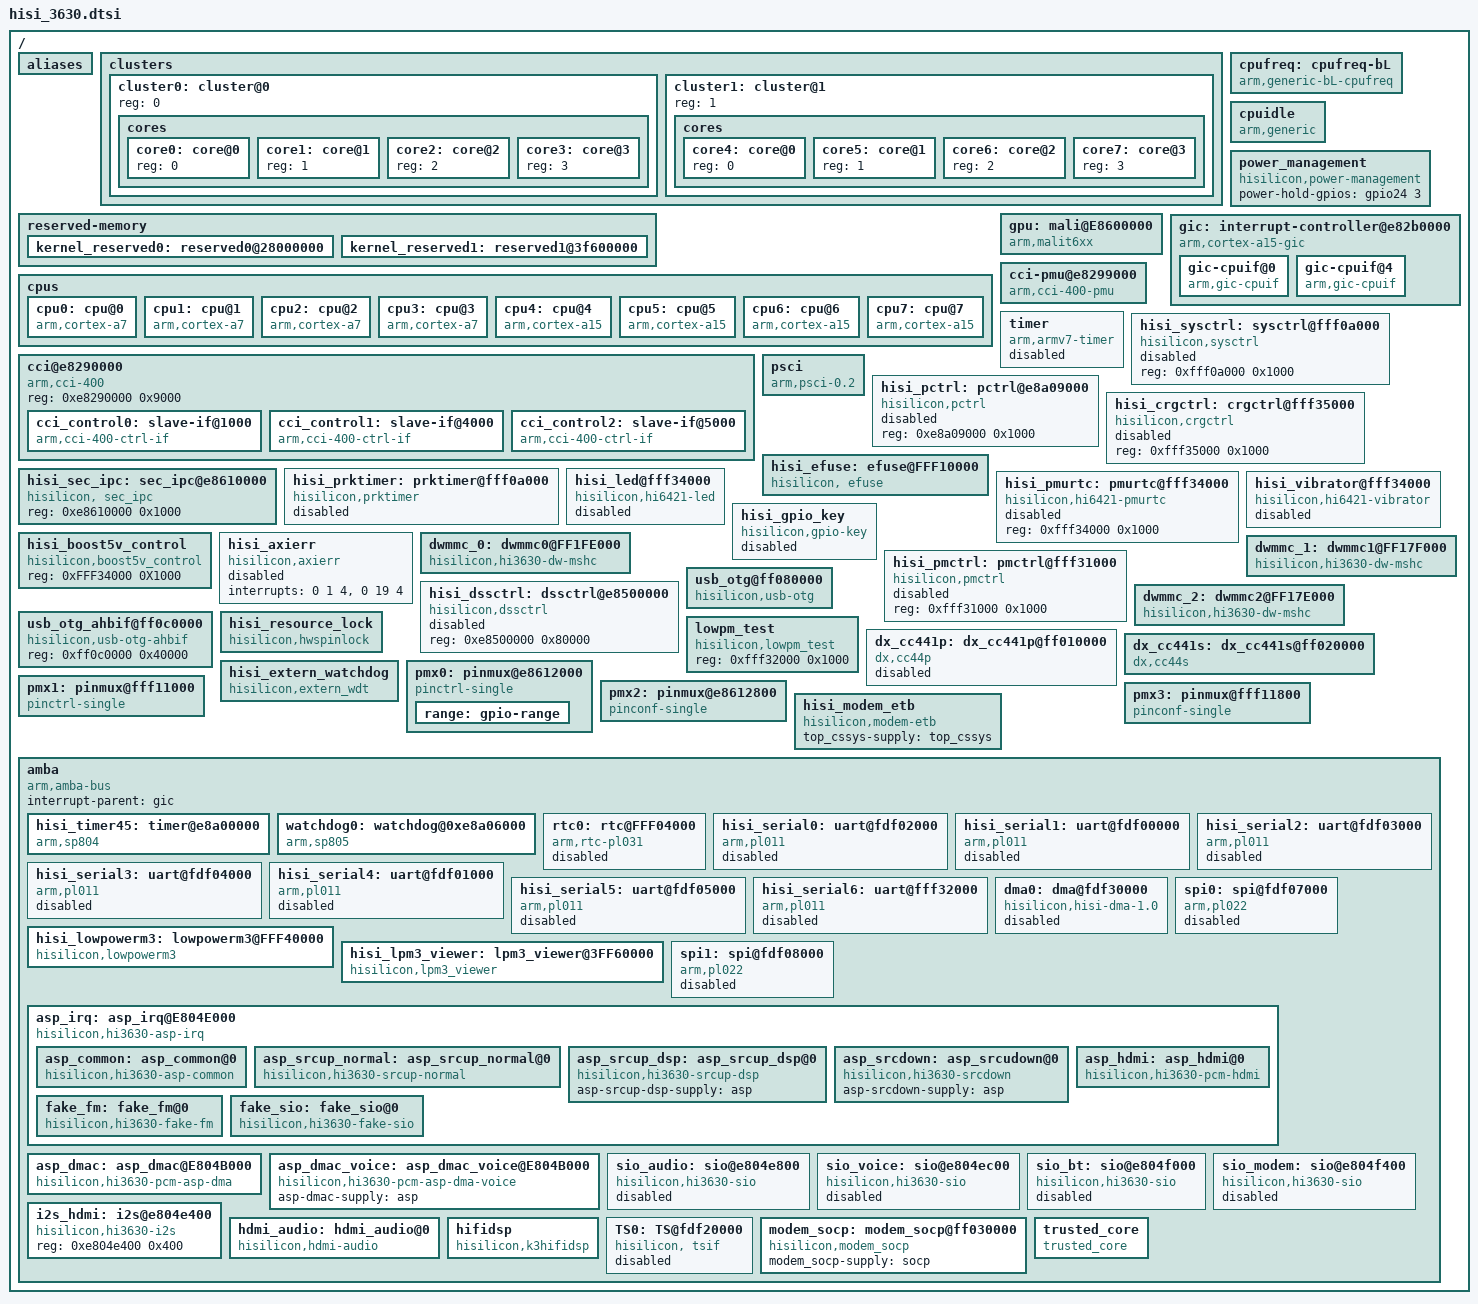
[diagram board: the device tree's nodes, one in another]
/*
 * Hisilicon Ltd. Hi3630FPGA SoC
 *
 * Copyright (C) 2013 Hisilicon Technologies CO., Ltd.
 *
 * This program is free software; you can redistribute it and/or modify
 * it under the terms of the GNU General Public License version 2 as
 * publishhed by the Free Software Foundation.
 */

/include/ "skeleton.dtsi"
/include/ "hisi_3630_clock.dtsi"
/include/ "hisi_3630_gpio.dtsi"
/include/ "hisi_3630_i2c.dtsi"
/include/ "hisi_3630_ipc.dtsi"
/{
	aliases {
		serial0 = &hisi_serial0;
	        serial1 = &hisi_serial1;
	        serial2 = &hisi_serial2;
	        serial3 = &hisi_serial3;
	        serial4 = &hisi_serial4;
	        serial5 = &hisi_serial5;
		serial6 = &hisi_serial6;

		mshc0 = &dwmmc_0;
		mshc1 = &dwmmc_1;
		mshc2 = &dwmmc_2;
	};

	clusters {
		#address-cells = <1>;
		#size-cells = <0>;

		cluster0: cluster@0 { /*A15 cluster*/
			reg = <0>;
			cores {
				#address-cells = <1>;
				#size-cells = <0>;

				core0: core@0 {
					reg = <0>;
				};

				core1: core@1 {
					reg = <1>;
				};

				core2: core@2 {
					reg = <2>;
				};

				core3: core@3 {
					reg = <3>;
				};

			};
		};

		cluster1: cluster@1 { /*A7 cluster*/
			reg = <1>;
			cores {
				#address-cells = <1>;
				#size-cells = <0>;

				core4: core@0 {
					reg = <0>;
				};

				core5: core@1 {
					reg = <1>;
				};

				core6: core@2 {
					reg = <2>;
				};

				core7: core@3 {
					reg = <3>;
				};
			};
		};
	};
	
	reserved-memory {
		#address-cells = <1>;
		#size-cells = <1>;
		ranges;

		kernel_reserved0: reserved0@28000000 {
			reg = <0x28000000 0x12a00000>;
			no-map;
		};

		kernel_reserved1: reserved1@3f600000 {
			reg = <0x3f600000 0x00a00000>;
			no-map;
		};

	};
	
	cpus {
		#address-cells = <1>;
		#size-cells = <0>;

		cpu0: cpu@0 {
			device_type = "cpu";
			compatible = "arm,cortex-a7";
			cci-control-port = <&cci_control1>;
			reg = <0x100>;
			cluster = <&cluster1>;
			core = <&core4>;
			clock-frequency = <0>;
			clock-latency = <0>;
			operating-points = <
				/* kHz */
				403200  0
				604800  0
				806400  0
				1017600 0
				1209600 0
				1305600 0
				/* 1401600 0 */
				/* 1612800 0 */
			>;
		};

		cpu1: cpu@1 {
			device_type = "cpu";
			compatible = "arm,cortex-a7";
			cci-control-port = <&cci_control1>;
			reg = <0x101>;
			cluster = <&cluster1>;
			core = <&core5>;
			clock-frequency = <0>;
			clock-latency = <0>;
		};

		cpu2: cpu@2 {
			device_type = "cpu";
			compatible = "arm,cortex-a7";
			cci-control-port = <&cci_control1>;
			reg = <0x102>;
			cluster = <&cluster1>;
			core = <&core6>;
			clock-frequency = <0>;
			clock-latency = <0>;
		};

		cpu3: cpu@3 {
			device_type = "cpu";
			compatible = "arm,cortex-a7";
			cci-control-port = <&cci_control1>;
			reg = <0x103>;
			cluster = <&cluster1>;
			core = <&core7>;
			clock-frequency = <0>;
			clock-latency = <0>;
		};

		cpu4: cpu@4 {
			device_type = "cpu";
			compatible = "arm,cortex-a15";
			cci-control-port = <&cci_control2>;
			reg = <0>;
			cluster = <&cluster0>;
			core = <&core0>;
			clock-frequency = <0>;
			clock-latency = <0>;
			operating-points = <
				/* kHz */
				/* 508800  0 */
				806400  0
				1017600 0
				1209600 0
				1382400 0
				1497600 0
				1708800 0
				/* 1804800 0 */
			>;
		};

		cpu5: cpu@5 {
			device_type = "cpu";
			compatible = "arm,cortex-a15";
			cci-control-port = <&cci_control2>;
			reg = <1>;
			cluster = <&cluster0>;
			core = <&core1>;
			clock-frequency = <0>;
			clock-latency = <0>;
		};

		cpu6: cpu@6 {
			device_type = "cpu";
			compatible = "arm,cortex-a15";
			cci-control-port = <&cci_control2>;
			reg = <2>;
			cluster = <&cluster0>;
			core = <&core2>;
			clock-frequency = <0>;
			clock-latency = <0>;
		};

		cpu7: cpu@7 {
			device_type = "cpu";
			compatible = "arm,cortex-a15";
			cci-control-port = <&cci_control2>;
			reg = <3>;
			cluster = <&cluster0>;
			core = <&core3>;
			clock-frequency = <0>;
			clock-latency = <0>;
		};
	};

	/* cpufreq  device */
	cpufreq: cpufreq-bL {
		compatible = "arm,generic-bL-cpufreq";
	};

    cpuidle {
        compatible = "arm,generic";
        status = "ok";
    };

	power_management {
		compatible = "hisilicon,power-management";
		power-hold-gpios = <&gpio24 3 0>;
	};

	gpu: mali@E8600000 {
		compatible = "arm,malit6xx", "arm,mali-midgard";
                reg = <0xE8600000 0x4000>;
                interrupts = <0 137 4  0 138 4  0 139 4>;
                interrupt-names = "JOB", "MMU", "GPU";
		clocks = <&clk_g3d>;
		gpu-supply = <&g3d>;
		operating-points = <
			/* kHz */
			288000 0
			360000 0
			480000 0
			600000 0
			/* 720000 0 */
		>;
	};

	gic: interrupt-controller@e82b0000 {
		compatible = "arm,cortex-a15-gic", "arm,cortex-a7-gic";
		#interrupt-cells = <3>;
		#address-cells = <0>;
		interrupt-controller;
		reg =	<0xe82b1000 0x1000>,
			<0xe82b2000 0x1000>,
			<0xe82b4000 0x2000>,
			<0xe82b6000 0x2000>;
		interrupts = <1 9 0xf04>;
		/*In our system, a15 cluster is in range cpuif0/cpuif1/cpuif2/cpuif3
		* a7 cluster is in range cpuif4/cpuif5/cpuif6/cpuif7
		*/
		gic-cpuif@0 {
			compatible = "arm,gic-cpuif";
			cpuif-id = <0>;
			cpu = <&cpu1>;
		};

		gic-cpuif@4 {
			compatible = "arm,gic-cpuif";
			cpuif-id = <4>;
			cpu = <&cpu0>;
		};
	};

        cci@e8290000 {
                compatible = "arm,cci-400";
                #address-cells = <1>;
                #size-cells = <1>;
                reg = <0xe8290000 0x9000>;
                ranges = <0x1000 0xe8291000 0x1000>,
			<0x4000 0xe8294000 0x1000>,
			<0x5000 0xe8295000 0x1000>;

                cci_control0: slave-if@1000 {
                        compatible = "arm,cci-400-ctrl-if";
                        interface-type = "ace-lite";
                        reg = <0x1000 0x1000>;
                };

                cci_control1: slave-if@4000 {
                        compatible = "arm,cci-400-ctrl-if";
                        interface-type = "ace";
                        reg = <0x4000 0x1000>;
                };

                cci_control2: slave-if@5000 {
                        compatible = "arm,cci-400-ctrl-if";
                        interface-type = "ace";
                        reg = <0x5000 0x1000>;
                };
        };

        cci-pmu@e8299000 {
                compatible = "arm,cci-400-pmu";
                reg = <0xe8299000 0x6000>;
                interrupts = <0 106 4>,
                             <0 107 4>;
        };

	timer {
		compatible = "arm,armv7-timer";
		interrupt-parent = <&gic>;
		clock-frequency = <19200000>;
		interrupts =
			<1 13 0xf08>,
			<1 14 0xf08>,
			<1 11 0xf08>,
			<1 10 0xf08>;
		status = "disabled";
	};

	hisi_sysctrl: sysctrl@fff0a000 {
		compatible = "hisilicon,sysctrl";
		reg = <0xfff0a000 0x1000>;
		status = "disabled";
	};

	psci {
		compatible      = "arm,psci-0.2", "arm,psci";
		method          = "smc";
		cpu_suspend     = <0x80100001>;
		cpu_off         = <0x80100002>;
		cpu_on          = <0x80100003>;
		migrate         = <0x80100004>;
		system_off      = <0x80100008>;
		system_reset    = <0x80100009>;
	};
	hisi_pctrl: pctrl@e8a09000 {
		compatible = "hisilicon,pctrl";
		reg = <0xe8a09000 0x1000>;
		status = "disabled";
	};

	hisi_crgctrl: crgctrl@fff35000 {
		compatible = "hisilicon,crgctrl";
		reg = <0xfff35000 0x1000>;
		status = "disabled";
	};

	hisi_efuse: efuse@FFF10000 {
		compatible = "hisilicon, efuse";
		reg = <0xFFF10000 0x1000>;
		efuse-burning-supply = <&ldo6>;
	};

	hisi_sec_ipc: sec_ipc@e8610000 {
		compatible = "hisilicon, sec_ipc";
		reg = <0xe8610000 0x1000>;
	};

	hisi_prktimer: prktimer@fff0a000 {
		compatible = "hisilicon,prktimer";
		fpga_flag = <0>;
		reg = <0xfff0a000 0x1000>;
		status = "disabled";
	};

	hisi_pmurtc: pmurtc@fff34000 {
		compatible = "hisilicon,hi6421-pmurtc";
		reg = <0xfff34000 0x1000>;
		status = "disabled";
	};

	hisi_led@fff34000 {
		compatible = "hisilicon,hi6421-led";
		reg = <0xfff34000 0x1000>;
		hi6421,dr3ctrl = "red";
		hi6421,dr4ctrl = "green";
		hi6421,dr5ctrl = "blue";
		status = "disabled";
	};

	hisi_vibrator@fff34000 {
		compatible = "hisilicon,hi6421-vibrator";
		reg = <0xfff34000 0x1000>;
		/* 1 vibrator working LRA,0 working ERM*/
		hisi,erm_lra = <1>;
		/* 0:2.7V  1:2.8V 2:3.0V 3:3.3V */
		hisi,dr2_test = <3>;
		/*20H:0V  3FH:max lm_dr2 00H:MIN -lm_dr2 */
		hisi,dr2_vset = <0x3f>;
		/* LRA mode ocp enable,1 : enable,0 : disable*/
		hisi,ocp_en = <1>;
		/* 0 : 4 ocp cycle ,1 : 8 ocp sycle*/
		hisi,ocp_sel = <0>;
		/*LRA mode get current change frequency*/
		hisi,freq = <0x20>;
		/*"enabled": create dev/tspdrv node,"disabled": no dev/tspdrv node*/
		hw,immersion = "disabled";
		status = "disabled";
	};

	hisi_gpio_key {
		compatible = "hisilicon,gpio-key";
		pinctrl-names = "default", "idle";
		pinctrl-0 = <&gpio203_cfg_func &gpio204_cfg_func>;
		pinctrl-1 = <&gpio203_cfg_idle &gpio204_cfg_idle>;
		gpio-keyup,gpio-irq = <&gpio25 3 0>;
		gpio-keydown,gpio-irq = <&gpio25 4 0>;
		status = "disabled";
	};

	hisi_boost5v_control {
		compatible = "hisilicon,boost5v_control";
		reg = <0xFFF34000 0X1000>;
		status = "ok";
	};

	hisi_axierr {
		compatible = "hisilicon,axierr";
		interrupts = <0 1 4>, <0 19 4>;
		status = "disabled";
	};

	/* emmc */
	dwmmc_0: dwmmc0@FF1FE000 {
		compatible = "hisilicon,hi3630-dw-mshc";
		reg = <0xFF1FE000 0x1000>;
		interrupts = <0 118 4>;
		#address-cells = <1>;
		#size-cells = <0>;
		clocks = <&clk_gate_mmc0>, <&clk_ppll0>;
		clock-names = "ciu", "biu";
	};

	/* sd */
	dwmmc_1: dwmmc1@FF17F000 {
		compatible = "hisilicon,hi3630-dw-mshc";
		reg = <0xFF17F000 0x1000>;
		interrupts = <0 119 4>;
		#address-cells = <1>;
		#size-cells = <0>;
		clocks = <&clk_gate_mmc1>, <&clk_ppll0>;
		clock-names = "ciu", "biu";
	};

	hisi_pmctrl: pmctrl@fff31000 {
		compatible = "hisilicon,pmctrl";
		reg = <0xfff31000 0x1000>;
		status = "disabled";
	};

	hisi_dssctrl: dssctrl@e8500000 {
		compatible = "hisilicon,dssctrl";
		reg = <0xe8500000 0x80000>;
		status = "disabled";
	};

	/* SDIO */
	dwmmc_2: dwmmc2@FF17E000 {
		compatible = "hisilicon,hi3630-dw-mshc";
		reg = <0xFF17E000 0x1000>;
		interrupts = <0 120 4>;
		#address-cells = <1>;
		#size-cells = <0>;
		clocks = <&clk_gate_mmc2>, <&clk_ppll0>;
		clock-names = "ciu", "biu";
	};

	usb_otg@ff080000 {
		compatible = "hisilicon,usb-otg";
		reg = <0xff080000 0x40000>;
		interrupts = <0 115 0x4>;
		otgdebugsubsys-supply = <&usb2otg>;
		eyePattern = <0x01ee66e7>;
	};

	usb_otg_ahbif@ff0c0000 {
		compatible = "hisilicon,usb-otg-ahbif";
		reg = <0xff0c0000 0x40000>;
	};

	hisi_resource_lock {
		compatible = "hisilicon,hwspinlock";
		hwlock,register-width = <32>;
		hwlock,bits-per-single = <4>;
		hwlock,groups = <8>;
		hwlock,offset = <0x400>, <0x40c>, <0x418>,
					<0x424>, <0x800>, <0x80c>,
					<0x818>, <0x824>;
	};

       lowpm_test {
               compatible = "hisilicon,lowpm_test";
	       reg = <0xfff32000 0x1000>;
       };

	dx_cc441p: dx_cc441p@ff010000 {
		compatible = "dx,cc44p";
		reg = <0xff010000 0x10000>;
		sec-p-buring-supply = <&sec_p>;
		interrupt-parent = <&gic>;
		interrupts = <0 109 4>;
		status = "disabled";
	};

	dx_cc441s: dx_cc441s@ff020000 {
		compatible = "dx,cc44s";
		reg = <0xff020000 0x10000>;
                sec-s-buring-supply = <&sec_s>;
	};

	hisi_extern_watchdog {
		compatible = "hisilicon,extern_wdt";
		reg = <0xe804d000 0x1000>;
		interrupts = <0 170 4>, <0 171 4>, <0 210 4>, <0 205 4>;
		status = "ok";
	};

	pmx0: pinmux@e8612000 {
		compatible = "pinctrl-single", "pinctrl-single0";
		reg = <0xe8612000 0x1f8>;
		#address-cells = <1>;
		#size-cells = <1>;
		#gpio-range-cells = <3>;
		ranges;

		pinctrl-single,register-width = <32>;
		pinctrl-single,function-mask = <7>;
		/* pin base, nr pins & gpio function */
		pinctrl-single,gpio-range = <&range 0 126 0>;

		range: gpio-range {
			#pinctrl-single,gpio-range-cells = <3>;
		};
	};

	pmx1: pinmux@fff11000 {
		compatible = "pinctrl-single", "pinctrl-single1";
		reg = <0xfff11000 0x84>;
		#address-cells = <1>;
		#size-cells = <1>;
		#gpio-range-cells = <3>;
		ranges;

		pinctrl-single,register-width = <32>;
		pinctrl-single,function-mask = <7>;
		/* pin base, nr pins & gpio function */
		pinctrl-single,gpio-range = <&range 0 33 0>;
	};

	pmx2: pinmux@e8612800 {
		compatible = "pinconf-single", "pinctrl-single2";
		reg = <0xe8612800 0x2c4>;
		#address-cells = <1>;
		#size-cells = <1>;
		ranges;

		pinctrl-single,register-width = <32>;
	};

	pmx3: pinmux@fff11800 {
		compatible = "pinconf-single", "pinctrl-single3";
		reg = <0xfff11800 0x98>;
		#address-cells = <1>;
		#size-cells = <1>;
		ranges;

		pinctrl-single,register-width = <32>;
	};

	hisi_modem_etb {
                compatible = "hisilicon,modem-etb";
                top_cssys-supply = <&top_cssys>;
                status = "ok";
        };

	amba{
		#address-cells = <1>;
		#size-cells = <1>;
		compatible = "arm,amba-bus";
		interrupt-parent = <&gic>;
		ranges;

		/*hisi_timer01: timer@fff00000 {
			compatible = "arm,sp804", "arm,primecell";
			reg = <0xfff00000 0x1000>;
			clocks = <&clk_gate_timclk0 &clk_gate_timclk0 &pclk>;
			clock-names = "clk_timclk0", "clk_timclk1","apb_pclk";
			interrupts = <0 36 4>,<0 37 4>;
			status = "disabled";
		};*/

		hisi_timer45: timer@e8a00000 {
			compatible = "arm,sp804", "arm,primecell";
			reg = <0xe8a00000 0x1000>;
			clocks = <&clk_gate_timclk4 &clk_gate_timclk4 &pclk>;
			clock-names = "clk_timclk4", "clk_timclk5","apb_pclk";
			interrupts = <0 44 4>,<0 45 4>;
			status = "ok";
		};

		watchdog0: watchdog@0xe8a06000 {
			compatible = "arm,sp805", "arm,primecell";
			reg = <0xe8a06000 0x1000>;
			default-timeout = <20>;
			interrupts = <0 52 4>;
			clocks = <&pclk_gate_wd0 &pclk>;
			clock-names = "pclk_wd0", "apb_pclk";
			status = "ok";
		};

		rtc0: rtc@FFF04000 {
				compatible = "arm,rtc-pl031", "arm,primecell";
				reg = <0xfff04000 0x1000>;
				interrupts = <0 54 0x4>;
				clocks = <&pclk>;
				clock-names = "apb_pclk";
				status = "disabled";
		};

		hisi_serial0: uart@fdf02000 {
			compatible = "arm,pl011", "arm,primecell";
			reg = <0xfdf02000 0x1000>;
			interrupts = <0 56 4>;
			fifo-deep-size = <64>;
			clk-enable-flag = <1>;
			clock-freq-high = <0>;
			clocks = <&clk_gate_uart0 &pclk>;
			clock-names = "clk_uart0", "apb_pclk";
			status = "disabled";
		};

		hisi_serial1: uart@fdf00000 {
			compatible = "arm,pl011", "arm,primecell";
			reg = <0xfdf00000 0x1000>;
			interrupts = <0 57 4>;
			dmas =	<&dma0 2          /* read channel */
				 &dma0 3>;        /* write channel */
			dma-names = "rx", "tx";
			fifo-deep-size = <64>;
			clk-enable-flag = <1>;
			clock-freq-high = <0>;
			clocks = <&clk_gate_uart1 &clk_gate_uart1>;
			clock-names = "clk_uart1", "apb_pclk";
			status = "disabled";
		};

		hisi_serial2: uart@fdf03000 {
			compatible = "arm,pl011", "arm,primecell";
			reg = <0xfdf03000 0x1000>;
			interrupts = <0 58 4>;
			dmas =	<&dma0 4	  /* read channel */
				 &dma0 5>;	  /* write channel */
			dma-names = "rx", "tx";
			fifo-deep-size = <64>;
			clk-enable-flag = <1>;
			clock-freq-high = <0>;
			clocks = <&clk_gate_uart2 &pclk>;
			clock-names = "clk_uart2", "apb_pclk";
			status = "disabled";

		};

		hisi_serial3: uart@fdf04000 {
			compatible = "arm,pl011", "arm,primecell";
			reg = <0xfdf04000 0x1000>;
			interrupts = <0 59 4>;

			dmas =	<&dma0 6	  /* read channel */
				 &dma0 7>;	  /* write channel */
			dma-names = "rx", "tx";

			fifo-deep-size = <64>;
			clk-enable-flag = <1>;
			clock-freq-high = <0>;
			clocks = <&clk_gate_uart3 &clk_gate_uart3>;
			clock-names = "clk_uart3", "apb_pclk";
			status = "disabled";
		};

		hisi_serial4: uart@fdf01000 {
			compatible = "arm,pl011", "arm,primecell";
			reg = <0xfdf01000 0x1000>;
			interrupts = <0 60 4>;
			dmas =	<&dma0 8	  /* read channel */
				 &dma0 9>;	  /* write channel */
			dma-names = "rx", "tx";
			fifo-deep-size = <64>;
			clk-enable-flag = <1>;
			clock-freq-high = <1>;
			clocks = <&clk_gate_uart4 &clk_gate_uart4>;
			clock-names = "clk_uart4", "apb_pclk";
			status = "disabled";
		};

		hisi_serial5: uart@fdf05000 {
			compatible = "arm,pl011", "arm,primecell";
			reg = <0xfdf05000 0x1000>;
			interrupts = <0 61 4>;
			dmas =	<&dma0 10	   /* read channel */
				 &dma0 11>;	   /* write channel */
			dma-names = "rx", "tx";
			fifo-deep-size = <64>;
			clk-enable-flag = <1>;
			clock-freq-high = <0>;
			clocks = <&clk_gate_uart5 &clk_gate_uart5>;
			clock-names = "clk_uart5", "apb_pclk";
			status = "disabled";

		};

		hisi_serial6: uart@fff32000 {
			compatible = "arm,pl011", "arm,primecell";
			reg = <0xfff32000 0x1000>;
			interrupts = <0 62 4>;
			fifo-deep-size = <64>;
			clk-enable-flag = <1>;
			clock-freq-high = <0>;
			clocks = <&clk_uart6 &pclk>;
			clock-names = "uart6clk", "apb_pclk";
			status = "disabled";
		};

		dma0: dma@fdf30000 {
			compatible = "hisilicon,hisi-dma-1.0";
			reg = <0xfdf30000 0x1000>;
			#dma-cells = <1>;
			dma-channels = <16>;
			dma-requests = <27>;
			dma-min-chan = <1>;
			dma-used-chans = <0xFFFE>;
			interrupts = <0 121 4>;
			clocks = <&clk_gate_dmac &pclk>;
			clock-names = "clk_dmac", "apb_pclk";
			status = "disabled";
		};

		hisi_lowpowerm3: lowpowerm3@FFF40000 {
			compatible = "hisilicon,lowpowerm3";
			reg = <0xFFF40000 0x18000>, <0xFFF34000 0x2000>;
			interrupts = <0 171 4>;
			clocks = <&clk_gate_dmac>;
			clock-names = "clk_dmac";
		};

		hisi_lpm3_viewer: lpm3_viewer@3FF60000 {
			compatible = "hisilicon,lpm3_viewer";
			reg = <0x3FF60000 0x20000>;
			period_time = <0>;
			status = "ok";
		};

		spi0: spi@fdf07000 {
			compatible = "arm,pl022", "arm,primecell";
			reg = <0xfdf07000 0x1000>;
			interrupts = <0 63 4>;
			clocks = <&clk_gate_spi0 &clk_gate_spi0>;
			clock-names = "clk_spi0", "apb_pclk";
			bus-id = <0>;
			enable-dma = <1>;
			dmas =	<&dma0 12	   /* read channel */
				 &dma0 13>;	   /* write channel */
			dma-names = "rx", "tx";
			num-cs = <4>;
			hardware-mutex = <0>;
			status = "disabled";
		};

		spi1: spi@fdf08000 {
			compatible = "arm,pl022", "arm,primecell";
			reg = <0xfdf08000 0x1000>;
			interrupts = <0 64 4>;
			clocks = <&clk_gate_spi1 &clk_gate_spi1>;
			clock-names = "clk_spi1", "apb_pclk";
			bus-id = <1>;
			enable-dma = <1>;
			dmas =	<&dma0 14	   /* read channel */
				 &dma0 15>;	   /* write channel */
			dma-names = "rx", "tx";
			num-cs = <1>;
			hardware-mutex = <0>;
			status = "disabled";
		};

		asp_irq: asp_irq@E804E000 {
			compatible = "hisilicon,hi3630-asp-irq";
			reg = <0xE804E000 0xA000>;
			#interrupt-cells = <2>;
			interrupt-controller;
			interrupts = <0 136 4>;
			interrupt-names = "asp_irq";
			status = "ok";
			asp_common: asp_common@0 {
				compatible = "hisilicon,hi3630-asp-common";
				status = "ok";
			};
			asp_srcup_normal: asp_srcup_normal@0 {
				compatible = "hisilicon,hi3630-srcup-normal";
				interrupt-parent = <&asp_irq>;
				interrupts = <1 0>;
				interrupt-names = "asp_srcup_normal";
				asp-srcup-normal-supply = <&asp>;
				status = "ok";
			};
			asp_srcup_dsp: asp_srcup_dsp@0 {
				compatible = "hisilicon,hi3630-srcup-dsp";
				asp-srcup-dsp-supply = <&asp>;
				status = "ok";
			};
			asp_srcdown: asp_srcudown@0 {
				compatible = "hisilicon,hi3630-srcdown";
				asp-srcdown-supply = <&asp>;
				status = "ok";
			};
			asp_hdmi: asp_hdmi@0 {
				compatible = "hisilicon,hi3630-pcm-hdmi";
				interrupt-parent = <&asp_irq>;
				interrupts = <0 0>;
				interrupt-names = "asp_irq_hdmi";
				hdmi-pcm-supply = <&asp>;
			};
			fake_fm: fake_fm@0 {
				compatible = "hisilicon,hi3630-fake-fm";
				status = "ok";
			};
			fake_sio: fake_sio@0 {
				compatible = "hisilicon,hi3630-fake-sio";
				status = "ok";
			};
		};
		asp_dmac: asp_dmac@E804B000 {
			compatible = "hisilicon,hi3630-pcm-asp-dma";
			reg = <0xE804B000 0x1000>;
			interrupts = <0 213 4>;
			interrupt-names = "asp_dma_irq";
			asp-dmac-supply = <&asp>;
			status = "ok";
		};
		asp_dmac_voice: asp_dmac_voice@E804B000 {
			compatible = "hisilicon,hi3630-pcm-asp-dma-voice";
			asp-dmac-supply = <&asp>;
			status = "ok";
		};
		sio_audio: sio@e804e800 {
			compatible = "hisilicon,hi3630-sio";
			reg = <0xe804e800 0x400>;
			sio-audio-supply = <&asp>;
			pinctrl-names = "default", "idle";
			pinctrl-0 = <&gpio183_pmx_func
				     &gpio184_pmx_func
				     &gpio185_pmx_func
				     &gpio186_pmx_func
				     &gpio183_cfg_func
				     &gpio184_cfg_func
				     &gpio185_cfg_func
				     &gpio186_cfg_func>;
			pinctrl-1 = <&gpio183_pmx_idle
				     &gpio184_pmx_idle
				     &gpio185_pmx_idle
				     &gpio186_pmx_idle
				     &gpio183_cfg_idle
				     &gpio184_cfg_idle
				     &gpio185_cfg_idle
				     &gpio186_cfg_idle>;
			status = "disable";
		};
		sio_voice: sio@e804ec00 {
			compatible = "hisilicon,hi3630-sio";
			reg = <0xe804ec00 0x400>;
			sio-voice-supply = <&asp>;
			pinctrl-names = "default", "idle";
			pinctrl-0 = <&gpio043_pmx_func
				     &gpio044_pmx_func
				     &gpio045_pmx_func
				     &gpio046_pmx_func
				     &gpio043_cfg_func
				     &gpio044_cfg_func
				     &gpio045_cfg_func
				     &gpio046_cfg_func>;
			pinctrl-1 = <&gpio043_pmx_idle
				     &gpio044_pmx_idle
				     &gpio045_pmx_idle
				     &gpio046_pmx_idle
				     &gpio043_cfg_idle
				     &gpio044_cfg_idle
				     &gpio045_cfg_idle
				     &gpio046_cfg_idle>;
			status = "disable";
		};
		sio_bt: sio@e804f000 {
			compatible = "hisilicon,hi3630-sio";
			reg = <0xe804f000 0x400>;
			sio-bt-supply = <&asp>;
			/*
			pinctrl-names = "default", "idle";
			pinctrl-0 = <&gpio187_pmx_func
				     &gpio188_pmx_func
				     &gpio189_pmx_func
				     &gpio190_pmx_func
				     &gpio187_cfg_func
				     &gpio188_cfg_func
				     &gpio189_cfg_func
				     &gpio190_cfg_func>;
			pinctrl-1 = <&gpio187_pmx_idle
				     &gpio188_pmx_idle
				     &gpio189_pmx_idle
				     &gpio190_pmx_idle
				     &gpio187_cfg_idle
				     &gpio188_cfg_idle
				     &gpio189_cfg_idle
				     &gpio190_cfg_idle>;
			*/
			status = "disable";
		};
		sio_modem: sio@e804f400 {
			compatible = "hisilicon,hi3630-sio";
			reg = <0xe804f400 0x400>;
			sio-modem-supply = <&asp>;
			/*
			pinctrl-names = "default", "idle";
			pinctrl-0 = <&gpio191_pmx_func
				     &gpio192_pmx_func
				     &gpio193_pmx_func
				     &gpio194_pmx_func
				     &gpio191_cfg_func
				     &gpio192_cfg_func
				     &gpio193_cfg_func
				     &gpio194_cfg_func>;
			pinctrl-1 = <&gpio191_pmx_idle
				     &gpio192_pmx_idle
				     &gpio193_pmx_idle
				     &gpio194_pmx_idle
				     &gpio191_cfg_idle
				     &gpio192_cfg_idle
				     &gpio193_cfg_idle
				     &gpio194_cfg_idle>;
			*/
			status = "disable";
		};
		i2s_hdmi: i2s@e804e400 {
			compatible = "hisilicon,hi3630-i2s";
			reg = <0xe804e400 0x400>;
		};
		hdmi_audio: hdmi_audio@0 {
			compatible = "hisilicon,hdmi-audio";
		};
		hifidsp {
			compatible = "hisilicon,k3hifidsp";
			hifimisc-supply =<&hifi>;
			reg = <0xE804E000 0x120>;
		};
	        TS0: TS@fdf20000 {
			compatible = "hisilicon, tsif";
			reg = <0xfdf20000 0x1000>;
			interrupts = <0 65 4>;
			dmas =	<&dma0 22>;	/* read channel */
			dma-names = "rx";
			status = "disabled";
		};
		modem_socp: modem_socp@ff030000 {
			compatible = "hisilicon,modem_socp";
			modem_socp-supply =<&socp>;
		};
		trusted_core {
			compatible = "trusted_core";
			interrupts = <0 206 4>;
			sec-s-buring-supply = <&sec_s>;
		};
	};
};
